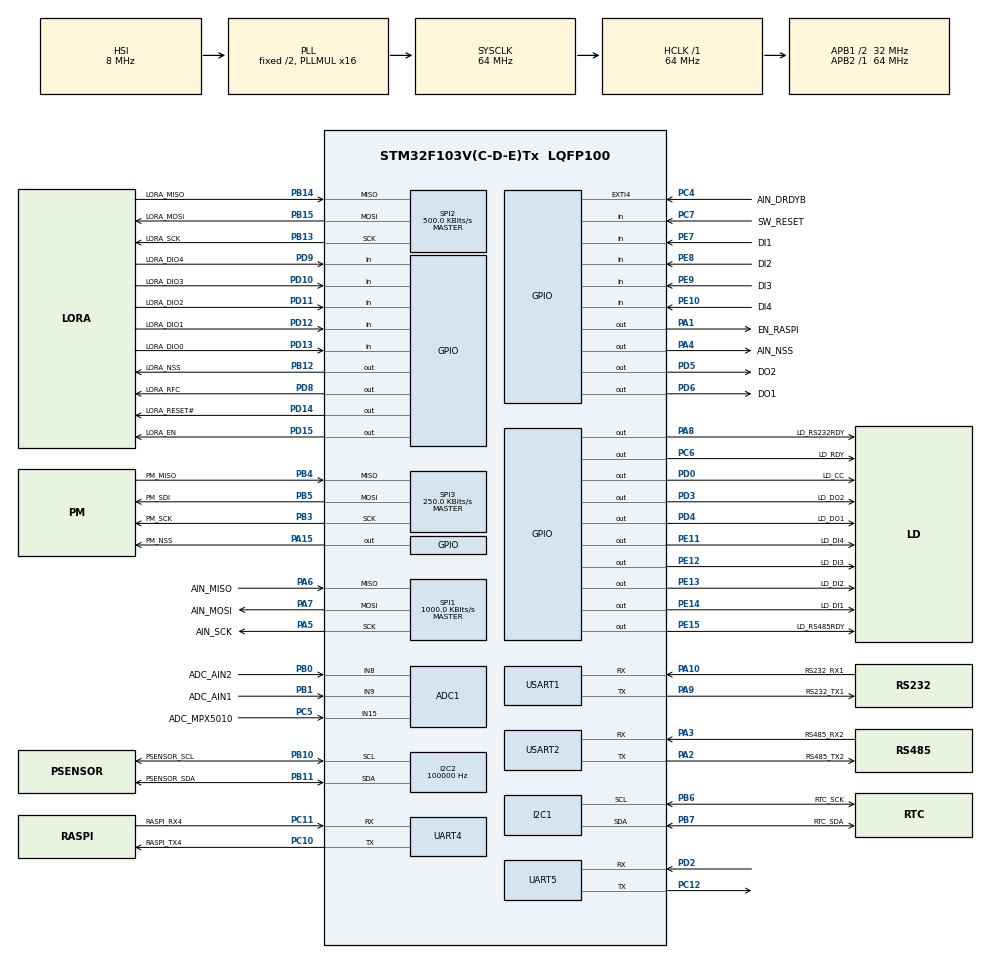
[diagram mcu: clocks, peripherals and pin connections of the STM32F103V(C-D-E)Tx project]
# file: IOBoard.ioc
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ADC1.Channel-0\#ChannelRegularConversion=ADC_CHANNEL_8
ADC1.Channel-1\#ChannelRegularConversion=ADC_CHANNEL_9
ADC1.Channel-2\#ChannelRegularConversion=ADC_CHANNEL_15
ADC1.Channel-3\#ChannelRegularConversion=ADC_CHANNEL_VREFINT
ADC1.NbrOfConversion=4
ADC1.NbrOfConversionFlag=1
ADC1.Rank-0\#ChannelRegularConversion=1
ADC1.Rank-1\#ChannelRegularConversion=2
ADC1.Rank-2\#ChannelRegularConversion=3
ADC1.Rank-3\#ChannelRegularConversion=4
ADC1.SamplingTime-0\#ChannelRegularConversion=ADC_SAMPLETIME_7CYCLES_5
ADC1.SamplingTime-1\#ChannelRegularConversion=ADC_SAMPLETIME_7CYCLES_5
ADC1.SamplingTime-2\#ChannelRegularConversion=ADC_SAMPLETIME_7CYCLES_5
ADC1.SamplingTime-3\#ChannelRegularConversion=ADC_SAMPLETIME_7CYCLES_5
ADC1.master=1
Dma.ADC1.3.Direction=DMA_PERIPH_TO_MEMORY
Dma.ADC1.3.Instance=DMA1_Channel1
Dma.ADC1.3.MemDataAlignment=DMA_MDATAALIGN_HALFWORD
Dma.ADC1.3.MemInc=DMA_MINC_ENABLE
Dma.ADC1.3.Mode=DMA_NORMAL
Dma.ADC1.3.PeriphDataAlignment=DMA_PDATAALIGN_HALFWORD
Dma.ADC1.3.PeriphInc=DMA_PINC_DISABLE
Dma.ADC1.3.Priority=DMA_PRIORITY_LOW
Dma.Request0=USART1_RX
Dma.Request1=USART2_RX
Dma.Request2=UART4_RX
Dma.Request3=ADC1
Dma.UART4_RX.2.Direction=DMA_PERIPH_TO_MEMORY
Dma.UART4_RX.2.Instance=DMA2_Channel3
Dma.UART4_RX.2.MemDataAlignment=DMA_MDATAALIGN_BYTE
Dma.UART4_RX.2.MemInc=DMA_MINC_ENABLE
Dma.UART4_RX.2.Mode=DMA_CIRCULAR
Dma.UART4_RX.2.PeriphDataAlignment=DMA_PDATAALIGN_BYTE
Dma.UART4_RX.2.PeriphInc=DMA_PINC_DISABLE
Dma.UART4_RX.2.Priority=DMA_PRIORITY_LOW
Dma.USART1_RX.0.Direction=DMA_PERIPH_TO_MEMORY
Dma.USART1_RX.0.Instance=DMA1_Channel5
Dma.USART1_RX.0.MemDataAlignment=DMA_MDATAALIGN_BYTE
Dma.USART1_RX.0.MemInc=DMA_MINC_ENABLE
Dma.USART1_RX.0.Mode=DMA_CIRCULAR
Dma.USART1_RX.0.PeriphDataAlignment=DMA_PDATAALIGN_BYTE
Dma.USART1_RX.0.PeriphInc=DMA_PINC_DISABLE
Dma.USART1_RX.0.Priority=DMA_PRIORITY_LOW
Dma.USART2_RX.1.Direction=DMA_PERIPH_TO_MEMORY
Dma.USART2_RX.1.Instance=DMA1_Channel6
Dma.USART2_RX.1.MemDataAlignment=DMA_MDATAALIGN_BYTE
Dma.USART2_RX.1.MemInc=DMA_MINC_ENABLE
Dma.USART2_RX.1.Mode=DMA_CIRCULAR
Dma.USART2_RX.1.PeriphDataAlignment=DMA_PDATAALIGN_BYTE
Dma.USART2_RX.1.PeriphInc=DMA_PINC_DISABLE
Dma.USART2_RX.1.Priority=DMA_PRIORITY_LOW
I2C2.ClockSpeed=100000
I2C2.I2C_Mode=I2C_Standard
I2C2.OwnAddress=0x28
IWDG.Prescaler=IWDG_PRESCALER_32
Mcu.Family=STM32F1
Mcu.Name=STM32F103V(C-D-E)Tx
Mcu.Package=LQFP100
Mcu.UserConstants=MCU_FREQ,64
NVIC.DMA1_Channel1_IRQn=true\:0\:0\:false\:false\:true\:false\:true
NVIC.DMA1_Channel5_IRQn=true\:0\:0\:false\:false\:true\:false\:true
NVIC.DMA1_Channel6_IRQn=true\:0\:0\:false\:false\:true\:false\:true
NVIC.DMA2_Channel3_IRQn=true\:0\:0\:false\:false\:true\:false\:true
NVIC.EXTI4_IRQn=true\:0\:0\:false\:false\:true\:true\:true
NVIC.PriorityGroup=NVIC_PRIORITYGROUP_4
NVIC.SPI1_IRQn=true\:0\:0\:false\:false\:true\:true\:true
NVIC.SPI2_IRQn=true\:0\:0\:false\:false\:true\:true\:true
NVIC.SPI3_IRQn=true\:0\:0\:false\:false\:true\:true\:true
NVIC.TIM5_IRQn=true\:0\:0\:false\:false\:true\:true\:true
NVIC.TIM6_IRQn=true\:0\:0\:false\:false\:true\:true\:true
NVIC.TIM7_IRQn=true\:0\:0\:false\:false\:true\:true\:true
OSC_IN.Mode=HSE-External-Oscillator
OSC_IN.Signal=RCC_OSC_IN
OSC_OUT.Mode=HSE-External-Oscillator
OSC_OUT.Signal=RCC_OSC_OUT
PA1.GPIO_Label=EN_RASPI
PA1.Signal=GPIO_Output
PA10.GPIO_Label=RS232_RX1
PA10.Mode=Asynchronous
PA10.Signal=USART1_RX
PA13.Mode=Serial_Wire
PA13.Signal=SYS_JTMS-SWDIO
PA14.Mode=Serial_Wire
PA14.Signal=SYS_JTCK-SWCLK
PA15.GPIO_Label=PM_NSS
PA15.Signal=GPIO_Output
PA2.GPIO_Label=RS485_TX2
PA2.Mode=Asynchronous
PA2.Signal=USART2_TX
PA3.GPIO_Label=RS485_RX2
PA3.Mode=Asynchronous
PA3.Signal=USART2_RX
PA4.GPIO_Label=AIN_NSS
PA4.Signal=GPIO_Output
PA5.GPIO_Label=AIN_SCK
PA5.Mode=Full_Duplex_Master
PA5.Signal=SPI1_SCK
PA6.GPIO_Label=AIN_MISO
PA6.Mode=Full_Duplex_Master
PA6.Signal=SPI1_MISO
PA7.GPIO_Label=AIN_MOSI
PA7.Mode=Full_Duplex_Master
PA7.Signal=SPI1_MOSI
PA8.GPIO_Label=LD_RS232RDY
PA8.Signal=GPIO_Output
PA9.GPIO_Label=RS232_TX1
PA9.Mode=Asynchronous
PA9.Signal=USART1_TX
PB0.GPIO_Label=ADC_AIN2
PB0.Signal=ADCx_IN8
PB1.GPIO_Label=ADC_AIN1
PB1.Signal=ADCx_IN9
PB10.GPIO_Label=PSENSOR_SCL
PB10.Mode=I2C
PB10.Signal=I2C2_SCL
PB11.GPIO_Label=PSENSOR_SDA
PB11.Mode=I2C
PB11.Signal=I2C2_SDA
PB12.GPIO_Label=LORA_NSS
PB12.Signal=GPIO_Output
PB13.GPIO_Label=LORA_SCK
PB13.Mode=Full_Duplex_Master
PB13.Signal=SPI2_SCK
PB14.GPIO_Label=LORA_MISO
PB14.Mode=Full_Duplex_Master
PB14.Signal=SPI2_MISO
PB15.GPIO_Label=LORA_MOSI
PB15.Mode=Full_Duplex_Master
PB15.Signal=SPI2_MOSI
PB3.GPIO_Label=PM_SCK
PB3.Mode=Full_Duplex_Master
PB3.Signal=SPI3_SCK
PB4.GPIO_Label=PM_MISO
PB4.Mode=Full_Duplex_Master
PB4.Signal=SPI3_MISO
PB5.GPIO_Label=PM_SDI
PB5.Mode=Full_Duplex_Master
PB5.Signal=SPI3_MOSI
PB6.GPIO_Label=RTC_SCK
PB6.Mode=I2C
PB6.Signal=I2C1_SCL
PB7.GPIO_Label=RTC_SDA
PB7.Mode=I2C
PB7.Signal=I2C1_SDA
PC10.GPIO_Label=RASPI_TX4
PC10.Mode=Asynchronous
PC10.Signal=UART4_TX
PC11.GPIO_Label=RASPI_RX4
PC11.Mode=Asynchronous
PC11.Signal=UART4_RX
PC12.Mode=Asynchronous
PC12.Signal=UART5_TX
PC14-OSC32_IN.Mode=LSE-External-Oscillator
PC14-OSC32_IN.Signal=RCC_OSC32_IN
PC15-OSC32_OUT.Mode=LSE-External-Oscillator
PC15-OSC32_OUT.Signal=RCC_OSC32_OUT
PC4.GPIO_Label=AIN_DRDYB
PC4.Signal=GPXTI4
PC5.GPIO_Label=ADC_MPX5010
PC5.Signal=ADCx_IN15
PC6.GPIO_Label=LD_RDY
PC6.Signal=GPIO_Output
PC7.GPIO_Label=SW_RESET
PC7.Signal=GPIO_Input
PD0.GPIO_Label=LD_CC
PD0.Signal=GPIO_Output
PD10.GPIO_Label=LORA_DIO3
PD10.Signal=GPIO_Input
PD11.GPIO_Label=LORA_DIO2
PD11.Signal=GPIO_Input
PD12.GPIO_Label=LORA_DIO1
PD12.Signal=GPIO_Input
PD13.GPIO_Label=LORA_DIO0
PD13.Signal=GPIO_Input
PD14.GPIO_Label=LORA_RESET\#
PD14.Signal=GPIO_Output
PD15.GPIO_Label=LORA_EN
PD15.Signal=GPIO_Output
PD2.Mode=Asynchronous
PD2.Signal=UART5_RX
PD3.GPIO_Label=LD_DO2
PD3.Signal=GPIO_Output
PD4.GPIO_Label=LD_DO1
PD4.Signal=GPIO_Output
PD5.GPIO_Label=DO2
PD5.Signal=GPIO_Output
PD6.GPIO_Label=DO1
PD6.Signal=GPIO_Output
PD8.GPIO_Label=LORA_RFC
PD8.Signal=GPIO_Output
PD9.GPIO_Label=LORA_DIO4
PD9.Signal=GPIO_Input
PE10.GPIO_Label=DI4
PE10.Signal=GPIO_Input
PE11.GPIO_Label=LD_DI4
PE11.Signal=GPIO_Output
PE12.GPIO_Label=LD_DI3
PE12.Signal=GPIO_Output
PE13.GPIO_Label=LD_DI2
PE13.Signal=GPIO_Output
PE14.GPIO_Label=LD_DI1
PE14.Signal=GPIO_Output
PE15.GPIO_Label=LD_RS485RDY
PE15.Signal=GPIO_Output
PE7.GPIO_Label=DI1
PE7.Signal=GPIO_Input
PE8.GPIO_Label=DI2
PE8.Signal=GPIO_Input
PE9.GPIO_Label=DI3
PE9.Signal=GPIO_Input
ProjectManager.HeapSize=0x200
ProjectManager.StackSize=0x400
ProjectManager.TargetToolchain=STM32CubeIDE
RCC.ADCPresc=RCC_ADCPCLK2_DIV6
RCC.AHBFreq_Value=64000000
RCC.APB1CLKDivider=RCC_HCLK_DIV2
RCC.APB1Freq_Value=32000000
RCC.APB1TimFreq_Value=64000000
RCC.APB2Freq_Value=64000000
RCC.APB2TimFreq_Value=64000000
RCC.HCLKFreq_Value=64000000
RCC.HSE_VALUE=6800000
RCC.PLLMUL=RCC_PLL_MUL16
RCC.RTCClockSelection=RCC_RTCCLKSOURCE_LSE
RCC.SYSCLKFreq_VALUE=64000000
RCC.SYSCLKSource=RCC_SYSCLKSOURCE_PLLCLK
RCC.USBFreq_Value=64000000
RTC.Format=RTC_FORMAT_BIN
RTC.Year=10
SH.ADCx_IN15.0=ADC1_IN15,IN15
SH.ADCx_IN8.0=ADC1_IN8,IN8
SH.ADCx_IN9.0=ADC1_IN9,IN9
SPI1.BaudRatePrescaler=SPI_BAUDRATEPRESCALER_64
SPI1.CalculateBaudRate=1000.0 KBits/s
SPI1.Direction=SPI_DIRECTION_2LINES
SPI1.Mode=SPI_MODE_MASTER
SPI1.VirtualType=VM_MASTER
SPI2.BaudRatePrescaler=SPI_BAUDRATEPRESCALER_64
SPI2.CalculateBaudRate=500.0 KBits/s
SPI2.Direction=SPI_DIRECTION_2LINES
SPI2.Mode=SPI_MODE_MASTER
SPI2.VirtualType=VM_MASTER
SPI3.BaudRatePrescaler=SPI_BAUDRATEPRESCALER_128
SPI3.CLKPhase=SPI_PHASE_2EDGE
SPI3.CLKPolarity=SPI_POLARITY_HIGH
SPI3.CalculateBaudRate=250.0 KBits/s
SPI3.Direction=SPI_DIRECTION_2LINES
SPI3.Mode=SPI_MODE_MASTER
SPI3.VirtualType=VM_MASTER
TIM5.AutoReloadPreload=TIM_AUTORELOAD_PRELOAD_DISABLE
TIM5.Period=10000-1
TIM5.Prescaler=(MCU_FREQ* 100)-1
TIM6.Period=1000-1
TIM6.Prescaler=MCU_FREQ-1
TIM7.Period=10000-1
TIM7.Prescaler=MCU_FREQ-1
UART4.VirtualMode=Asynchronous
UART5.VirtualMode=Asynchronous
USART1.VirtualMode=VM_ASYNC
USART2.VirtualMode=VM_ASYNC
VP_ADC1_Vref_Input.Mode=IN-Vrefint
VP_IWDG_VS_IWDG.Mode=IWDG_Activate
VP_RTC_VS_RTC_Activate.Mode=RTC_Enabled
VP_RTC_VS_RTC_Calendar.Mode=RTC_Calendar
VP_TIM5_VS_ClockSourceINT.Mode=Internal
VP_TIM6_VS_ClockSourceINT.Mode=Enable_Timer
VP_TIM7_VS_ClockSourceINT.Mode=Enable_Timer
board=custom

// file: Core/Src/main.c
/* USER CODE BEGIN Header */
/**
  ******************************************************************************
  * @file           : main.c
  * @brief          : Main program body
  ******************************************************************************
  * @attention
  *
  * <h2><center>&copy; Copyright (c) 2020 STMicroelectronics.
  * All rights reserved.</center></h2>
  *
  * This software component is licensed by ST under BSD 3-Clause license,
  * the "License"; You may not use this file except in compliance with the
  * License. You may obtain a copy of the License at:
  *                        opensource.org/licenses/BSD-3-Clause
  *
  ******************************************************************************
  */
/* USER CODE END Header */
#include "main.h"
#include "adc.h"
#include "dma.h"
#include "i2c.h"
#include "iwdg.h"
#include "rtc.h"
#include "spi.h"
#include "tim.h"
#include "usart.h"
#include "gpio.h"

/* USER CODE BEGIN Includes */
#include "user.h"
#include "flash.h"
/* USER CODE END Includes */

void SystemClock_Config(void);

int main(void)
{

  /* MCU Configuration--------------------------------------------------------*/

  /* Reset of all peripherals, Initializes the Flash interface and the Systick. */
  HAL_Init();

  /* Configure the system clock */
  SystemClock_Config();

  /* USER CODE BEGIN SysInit */
#ifdef COMPILE_BOOTLOADER
  bootloader();
#else
  SCB->VTOR = FLASH_APPLECATION_ADDRESS_START;
  /* USER CODE END SysInit */

  /* Initialize all configured peripherals */
  MX_GPIO_Init();
  MX_DMA_Init();
  MX_RTC_Init();
  MX_TIM6_Init();
  MX_TIM7_Init();
  MX_IWDG_Init();
  MX_I2C1_Init();
  MX_I2C2_Init();
  MX_SPI2_Init();
  MX_SPI3_Init();
  MX_USART1_UART_Init();
  MX_USART2_UART_Init();
  MX_UART4_Init();
  MX_SPI1_Init();
  MX_UART5_Init();
  MX_TIM5_Init();
  MX_ADC1_Init();
  /* USER CODE BEGIN 2 */
  userStart();
  /* USER CODE END 2 */

  /* Infinite loop */
  /* USER CODE BEGIN WHILE */
  while (1)
  {
    userLoop();
    /* USER CODE END WHILE */

    /* USER CODE BEGIN 3 */
  }
#endif
  /* USER CODE END 3 */
}

void SystemClock_Config(void)
{
  RCC_OscInitTypeDef RCC_OscInitStruct = {0};
  RCC_ClkInitTypeDef RCC_ClkInitStruct = {0};
  RCC_PeriphCLKInitTypeDef PeriphClkInit = {0};

  /** Initializes the RCC Oscillators according to the specified parameters
  * in the RCC_OscInitTypeDef structure.
  */
  RCC_OscInitStruct.OscillatorType = RCC_OSCILLATORTYPE_HSI|RCC_OSCILLATORTYPE_LSI
                              |RCC_OSCILLATORTYPE_LSE;
  RCC_OscInitStruct.LSEState = RCC_LSE_ON;
  RCC_OscInitStruct.HSIState = RCC_HSI_ON;
  RCC_OscInitStruct.HSICalibrationValue = RCC_HSICALIBRATION_DEFAULT;
  RCC_OscInitStruct.LSIState = RCC_LSI_ON;
  RCC_OscInitStruct.PLL.PLLState = RCC_PLL_ON;
  RCC_OscInitStruct.PLL.PLLSource = RCC_PLLSOURCE_HSI_DIV2;
  RCC_OscInitStruct.PLL.PLLMUL = RCC_PLL_MUL16;
  if (HAL_RCC_OscConfig(&RCC_OscInitStruct) != HAL_OK)
  {
    Error_Handler();
  }
  /** Initializes the CPU, AHB and APB buses clocks
  */
  RCC_ClkInitStruct.ClockType = RCC_CLOCKTYPE_HCLK|RCC_CLOCKTYPE_SYSCLK
                              |RCC_CLOCKTYPE_PCLK1|RCC_CLOCKTYPE_PCLK2;
  RCC_ClkInitStruct.SYSCLKSource = RCC_SYSCLKSOURCE_PLLCLK;
  RCC_ClkInitStruct.AHBCLKDivider = RCC_SYSCLK_DIV1;
  RCC_ClkInitStruct.APB1CLKDivider = RCC_HCLK_DIV2;
  RCC_ClkInitStruct.APB2CLKDivider = RCC_HCLK_DIV1;

  if (HAL_RCC_ClockConfig(&RCC_ClkInitStruct, FLASH_LATENCY_2) != HAL_OK)
  {
    Error_Handler();
  }
  PeriphClkInit.PeriphClockSelection = RCC_PERIPHCLK_RTC|RCC_PERIPHCLK_ADC;
  PeriphClkInit.RTCClockSelection = RCC_RTCCLKSOURCE_LSE;
  PeriphClkInit.AdcClockSelection = RCC_ADCPCLK2_DIV6;
  if (HAL_RCCEx_PeriphCLKConfig(&PeriphClkInit) != HAL_OK)
  {
    Error_Handler();
  }
}

void Error_Handler(void)
{
}

/************************ (C) COPYRIGHT STMicroelectronics *****END OF FILE****/
